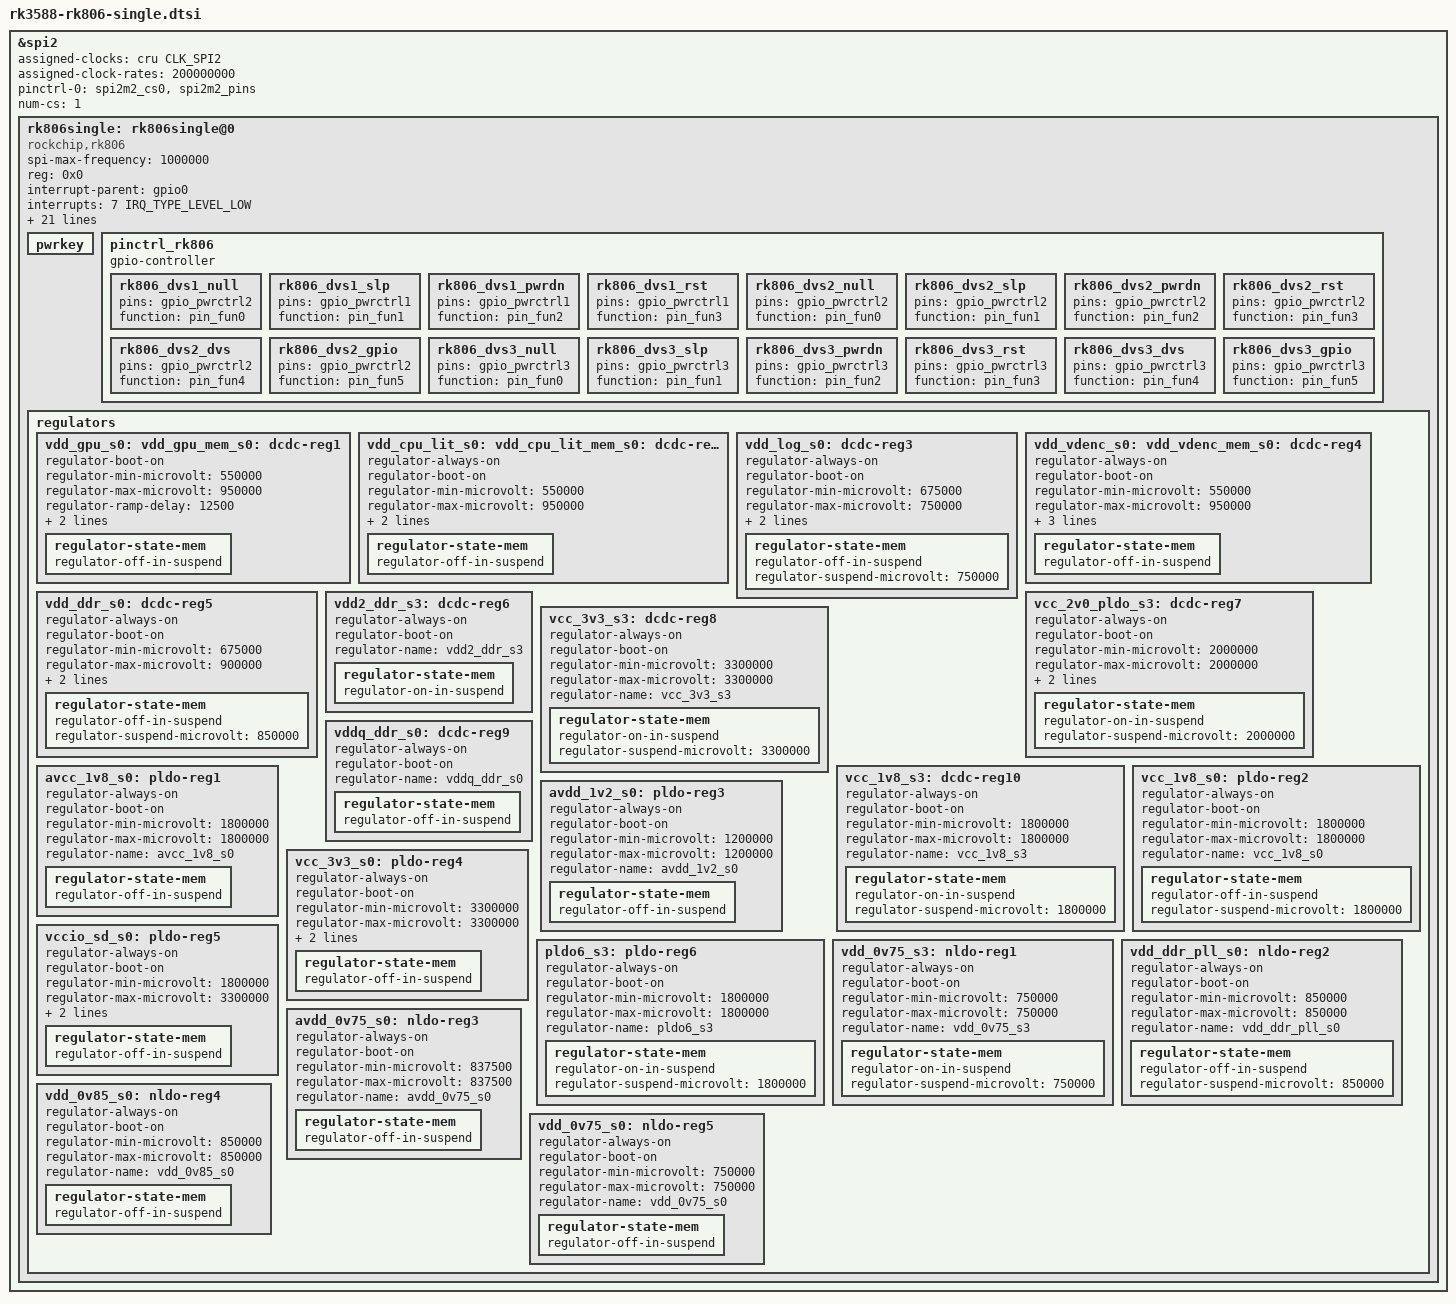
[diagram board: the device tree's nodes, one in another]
// SPDX-License-Identifier: (GPL-2.0+ OR MIT)
/*
 * Copyright (c) 2021 Rockchip Electronics Co., Ltd.
 *
 */

#include <dt-bindings/gpio/gpio.h>
#include <dt-bindings/pinctrl/rockchip.h>

&spi2 {
	status = "okay";
	assigned-clocks = <&cru CLK_SPI2>;
	assigned-clock-rates = <200000000>;
	pinctrl-names = "default";
	pinctrl-0 = <&spi2m2_cs0 &spi2m2_pins>;
	num-cs = <1>;

	rk806single: rk806single@0 {
		compatible = "rockchip,rk806";
		spi-max-frequency = <1000000>;
		reg = <0x0>;

		interrupt-parent = <&gpio0>;
		interrupts = <7 IRQ_TYPE_LEVEL_LOW>;

		pinctrl-names = "default";
		pinctrl-0 = <&pmic_pins>, <&rk806_dvs1_null>, <&rk806_dvs2_null>, <&rk806_dvs3_null>;

		/* 2800mv-3500mv */
		low_voltage_threshold = <3000>;
		/* 2700mv-3400mv */
		shutdown_voltage_threshold = <2700>;
		/* 140 160 */
		shutdown_temperture_threshold = <160>;
		hotdie_temperture_threshold = <115>;

		vcc1-supply = <&vcc5v0_sys>;
		vcc2-supply = <&vcc5v0_sys>;
		vcc3-supply = <&vcc5v0_sys>;
		vcc4-supply = <&vcc5v0_sys>;
		vcc5-supply = <&vcc5v0_sys>;
		vcc6-supply = <&vcc5v0_sys>;
		vcc7-supply = <&vcc5v0_sys>;
		vcc8-supply = <&vcc5v0_sys>;
		vcc9-supply = <&vcc5v0_sys>;
		vcc10-supply = <&vcc5v0_sys>;
		vcc11-supply = <&vcc_2v0_pldo_s3>;
		vcc12-supply = <&vcc5v0_sys>;
		vcc13-supply = <&vcc_1v1_nldo_s3>;
		vcc14-supply = <&vcc_1v1_nldo_s3>;
		vcca-supply = <&vcc5v0_sys>;

		pwrkey {
			status = "okay";
		};

		pinctrl_rk806: pinctrl_rk806 {
			gpio-controller;
			#gpio-cells = <2>;

			rk806_dvs1_null: rk806_dvs1_null {
				pins = "gpio_pwrctrl2";
				function = "pin_fun0";
			};

			rk806_dvs1_slp: rk806_dvs1_slp {
				pins = "gpio_pwrctrl1";
				function = "pin_fun1";
			};

			rk806_dvs1_pwrdn: rk806_dvs1_pwrdn {
				pins = "gpio_pwrctrl1";
				function = "pin_fun2";
			};

			rk806_dvs1_rst: rk806_dvs1_rst {
				pins = "gpio_pwrctrl1";
				function = "pin_fun3";
			};

			rk806_dvs2_null: rk806_dvs2_null {
				pins = "gpio_pwrctrl2";
				function = "pin_fun0";
			};

			rk806_dvs2_slp: rk806_dvs2_slp {
				pins = "gpio_pwrctrl2";
				function = "pin_fun1";
			};

			rk806_dvs2_pwrdn: rk806_dvs2_pwrdn {
				pins = "gpio_pwrctrl2";
				function = "pin_fun2";
			};

			rk806_dvs2_rst: rk806_dvs2_rst {
				pins = "gpio_pwrctrl2";
				function = "pin_fun3";
			};

			rk806_dvs2_dvs: rk806_dvs2_dvs {
				pins = "gpio_pwrctrl2";
				function = "pin_fun4";
			};

			rk806_dvs2_gpio: rk806_dvs2_gpio {
				pins = "gpio_pwrctrl2";
				function = "pin_fun5";
			};

			rk806_dvs3_null: rk806_dvs3_null {
				pins = "gpio_pwrctrl3";
				function = "pin_fun0";
			};

			rk806_dvs3_slp: rk806_dvs3_slp {
				pins = "gpio_pwrctrl3";
				function = "pin_fun1";
			};

			rk806_dvs3_pwrdn: rk806_dvs3_pwrdn {
				pins = "gpio_pwrctrl3";
				function = "pin_fun2";
			};

			rk806_dvs3_rst: rk806_dvs3_rst {
				pins = "gpio_pwrctrl3";
				function = "pin_fun3";
			};

			rk806_dvs3_dvs: rk806_dvs3_dvs {
				pins = "gpio_pwrctrl3";
				function = "pin_fun4";
			};

			rk806_dvs3_gpio: rk806_dvs3_gpio {
				pins = "gpio_pwrctrl3";
				function = "pin_fun5";
			};
		};

		regulators {
			vdd_gpu_s0: vdd_gpu_mem_s0: dcdc-reg1 {
				regulator-boot-on;
				regulator-min-microvolt = <550000>;
				regulator-max-microvolt = <950000>;
				regulator-ramp-delay = <12500>;
				regulator-name = "vdd_gpu_s0";
				regulator-enable-ramp-delay = <400>;
				regulator-state-mem {
					regulator-off-in-suspend;
				};
			};

			vdd_cpu_lit_s0: vdd_cpu_lit_mem_s0: dcdc-reg2 {
				regulator-always-on;
				regulator-boot-on;
				regulator-min-microvolt = <550000>;
				regulator-max-microvolt = <950000>;
				regulator-ramp-delay = <12500>;
				regulator-name = "vdd_cpu_lit_s0";
				regulator-state-mem {
					regulator-off-in-suspend;
				};
			};

			vdd_log_s0: dcdc-reg3 {
				regulator-always-on;
				regulator-boot-on;
				regulator-min-microvolt = <675000>;
				regulator-max-microvolt = <750000>;
				regulator-ramp-delay = <12500>;
				regulator-name = "vdd_log_s0";
				regulator-state-mem {
					regulator-off-in-suspend;
					regulator-suspend-microvolt = <750000>;
				};
			};

			vdd_vdenc_s0: vdd_vdenc_mem_s0: dcdc-reg4 {
				regulator-always-on;
				regulator-boot-on;
				regulator-min-microvolt = <550000>;
				regulator-max-microvolt = <950000>;
				regulator-init-microvolt = <750000>;
				regulator-ramp-delay = <12500>;
				regulator-name = "vdd_vdenc_s0";
				regulator-state-mem {
					regulator-off-in-suspend;
				};
			};

			vdd_ddr_s0: dcdc-reg5 {
				regulator-always-on;
				regulator-boot-on;
				regulator-min-microvolt = <675000>;
				regulator-max-microvolt = <900000>;
				regulator-ramp-delay = <12500>;
				regulator-name = "vdd_ddr_s0";
				regulator-state-mem {
					regulator-off-in-suspend;
					regulator-suspend-microvolt = <850000>;
				};
			};

			vdd2_ddr_s3: dcdc-reg6 {
				regulator-always-on;
				regulator-boot-on;
				regulator-name = "vdd2_ddr_s3";
				regulator-state-mem {
					regulator-on-in-suspend;
				};
			};

			vcc_2v0_pldo_s3: dcdc-reg7 {
				regulator-always-on;
				regulator-boot-on;
				regulator-min-microvolt = <2000000>;
				regulator-max-microvolt = <2000000>;
				regulator-ramp-delay = <12500>;
				regulator-name = "vdd_2v0_pldo_s3";
				regulator-state-mem {
					regulator-on-in-suspend;
					regulator-suspend-microvolt = <2000000>;
				};
			};

			vcc_3v3_s3: dcdc-reg8 {
				regulator-always-on;
				regulator-boot-on;
				regulator-min-microvolt = <3300000>;
				regulator-max-microvolt = <3300000>;
				regulator-name = "vcc_3v3_s3";
				regulator-state-mem {
					regulator-on-in-suspend;
					regulator-suspend-microvolt = <3300000>;
				};
			};

			vddq_ddr_s0: dcdc-reg9 {
				regulator-always-on;
				regulator-boot-on;
				regulator-name = "vddq_ddr_s0";
				regulator-state-mem {
					regulator-off-in-suspend;
				};
			};

			vcc_1v8_s3: dcdc-reg10 {
				regulator-always-on;
				regulator-boot-on;
				regulator-min-microvolt = <1800000>;
				regulator-max-microvolt = <1800000>;
				regulator-name = "vcc_1v8_s3";
				regulator-state-mem {
					regulator-on-in-suspend;
					regulator-suspend-microvolt = <1800000>;
				};
			};

			avcc_1v8_s0: pldo-reg1 {
				regulator-always-on;
				regulator-boot-on;
				regulator-min-microvolt = <1800000>;
				regulator-max-microvolt = <1800000>;
				regulator-name = "avcc_1v8_s0";
				regulator-state-mem {
					regulator-off-in-suspend;
				};
			};

			vcc_1v8_s0: pldo-reg2 {
				regulator-always-on;
				regulator-boot-on;
				regulator-min-microvolt = <1800000>;
				regulator-max-microvolt = <1800000>;
				regulator-name = "vcc_1v8_s0";
				regulator-state-mem {
					regulator-off-in-suspend;
					regulator-suspend-microvolt = <1800000>;
				};
			};

			avdd_1v2_s0: pldo-reg3 {
				regulator-always-on;
				regulator-boot-on;
				regulator-min-microvolt = <1200000>;
				regulator-max-microvolt = <1200000>;
				regulator-name = "avdd_1v2_s0";
				regulator-state-mem {
					regulator-off-in-suspend;
				};
			};

			vcc_3v3_s0: pldo-reg4 {
				regulator-always-on;
				regulator-boot-on;
				regulator-min-microvolt = <3300000>;
				regulator-max-microvolt = <3300000>;
				regulator-ramp-delay = <12500>;
				regulator-name = "vcc_3v3_s0";
				regulator-state-mem {
					regulator-off-in-suspend;
				};
			};

			vccio_sd_s0: pldo-reg5 {
				regulator-always-on;
				regulator-boot-on;
				regulator-min-microvolt = <1800000>;
				regulator-max-microvolt = <3300000>;
				regulator-ramp-delay = <12500>;
				regulator-name = "vccio_sd_s0";
				regulator-state-mem {
					regulator-off-in-suspend;
				};
			};

			pldo6_s3: pldo-reg6 {
				regulator-always-on;
				regulator-boot-on;
				regulator-min-microvolt = <1800000>;
				regulator-max-microvolt = <1800000>;
				regulator-name = "pldo6_s3";
				regulator-state-mem {
					regulator-on-in-suspend;
					regulator-suspend-microvolt = <1800000>;
				};
			};

			vdd_0v75_s3: nldo-reg1 {
				regulator-always-on;
				regulator-boot-on;
				regulator-min-microvolt = <750000>;
				regulator-max-microvolt = <750000>;
				regulator-name = "vdd_0v75_s3";
				regulator-state-mem {
					regulator-on-in-suspend;
					regulator-suspend-microvolt = <750000>;
				};
			};

			vdd_ddr_pll_s0: nldo-reg2 {
				regulator-always-on;
				regulator-boot-on;
				regulator-min-microvolt = <850000>;
				regulator-max-microvolt = <850000>;
				regulator-name = "vdd_ddr_pll_s0";
				regulator-state-mem {
					regulator-off-in-suspend;
					regulator-suspend-microvolt = <850000>;
				};
			};

			avdd_0v75_s0: nldo-reg3 {
				regulator-always-on;
				regulator-boot-on;
				regulator-min-microvolt = <837500>;
				regulator-max-microvolt = <837500>;
				regulator-name = "avdd_0v75_s0";
				regulator-state-mem {
					regulator-off-in-suspend;
				};
			};

			vdd_0v85_s0: nldo-reg4 {
				regulator-always-on;
				regulator-boot-on;
				regulator-min-microvolt = <850000>;
				regulator-max-microvolt = <850000>;
				regulator-name = "vdd_0v85_s0";
				regulator-state-mem {
					regulator-off-in-suspend;
				};
			};

			vdd_0v75_s0: nldo-reg5 {
				regulator-always-on;
				regulator-boot-on;
				regulator-min-microvolt = <750000>;
				regulator-max-microvolt = <750000>;
				regulator-name = "vdd_0v75_s0";
				regulator-state-mem {
					regulator-off-in-suspend;
				};
			};
		};
	};
};
